# nrf7140_sysctrl register map
Vendor: Nordic Semiconductor; Series: nRF71; File version: 1
Registers are 32-bit, read-write, reset 0x0 unless marked. A register's access mark holds for its fields unless they carry their own. Offsets are from the block's base; [hi:lo] are bit positions; lines under a group give offsets from that group; {n}, {i} and the like mark numbered series; 'fields as' and 'values as' point back to an identical list.

## VREGMAIN — VREGMAIN peripheral
Base 0x5F961000
0x100 EVENTS_READY — Power up done
  [0] EVENTS_READY
    0=NotGenerated (Event not generated); 1=Generated (Event generated)
0x104 EVENTS_SETTLED — Settled flag for MODE handshake
  [0] EVENTS_SETTLED
    values as EVENTS_READY.EVENTS_READY
{0x104+4i} EVENTS_SETTLEDCH{i} (i=1..3) — Settled flag for CH{i} enable
  [0] EVENTS_SETTLEDCH{i}
    values as EVENTS_READY.EVENTS_READY
0x114 EVENTS_IOUTCMP — Analog current comparator
  [0] EVENTS_IOUTCMP
    values as EVENTS_READY.EVENTS_READY
0x118 EVENTS_LP2HP — Current consumption above threshold
  [0] EVENTS_LP2HP
    values as EVENTS_READY.EVENTS_READY
0x11C EVENTS_HP2LP — Current consumption below threshold
  [0] EVENTS_HP2LP
    values as EVENTS_READY.EVENTS_READY
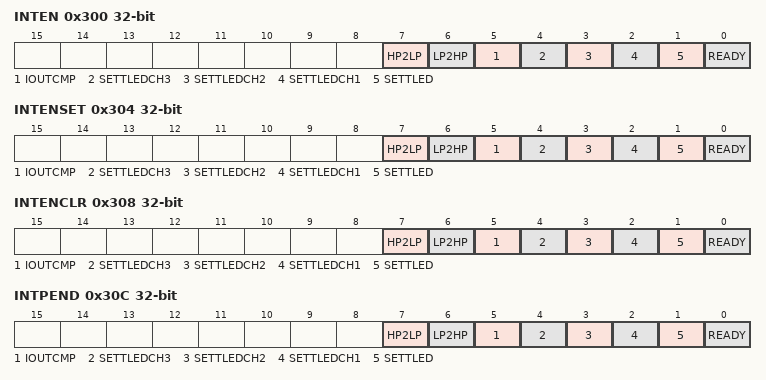
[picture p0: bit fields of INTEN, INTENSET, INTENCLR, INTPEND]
0x300 INTEN — Enable or disable interrupt
  [all] fields
    0=Disabled; 1=Enabled
  [7] HP2LP — Enable or disable interrupt for event HP2LP
  [6] LP2HP — Enable or disable interrupt for event LP2HP
  [5] IOUTCMP — Enable or disable interrupt for event IOUTCMP
  [4] SETTLEDCH3 — Enable or disable interrupt for event SETTLEDCH3
  [3] SETTLEDCH2 — Enable or disable interrupt for event SETTLEDCH2
  [2] SETTLEDCH1 — Enable or disable interrupt for event SETTLEDCH1
  [1] SETTLED — Enable or disable interrupt for event SETTLED
  [0] READY — Enable or disable interrupt for event READY
0x304 INTENSET — Enable interrupt
  [all] fields
    on read: 0=Disabled (Read: Disabled); 1=Enabled (Read: Enabled) | on write: 1=Set (Enable)
  [7] HP2LP — Write '1' to enable interrupt for event HP2LP
  [6] LP2HP — Write '1' to enable interrupt for event LP2HP
  [5] IOUTCMP — Write '1' to enable interrupt for event IOUTCMP
  [4] SETTLEDCH3 — Write '1' to enable interrupt for event SETTLEDCH3
  [3] SETTLEDCH2 — Write '1' to enable interrupt for event SETTLEDCH2
  [2] SETTLEDCH1 — Write '1' to enable interrupt for event SETTLEDCH1
  [1] SETTLED — Write '1' to enable interrupt for event SETTLED
  [0] READY — Write '1' to enable interrupt for event READY
0x308 INTENCLR — Disable interrupt
  [all] fields
    on read: 0=Disabled (Read: Disabled); 1=Enabled (Read: Enabled) | on write: 1=Clear (Disable)
  [7] HP2LP — Write '1' to disable interrupt for event HP2LP
  [6] LP2HP — Write '1' to disable interrupt for event LP2HP
  [5] IOUTCMP — Write '1' to disable interrupt for event IOUTCMP
  [4] SETTLEDCH3 — Write '1' to disable interrupt for event SETTLEDCH3
  [3] SETTLEDCH2 — Write '1' to disable interrupt for event SETTLEDCH2
  [2] SETTLEDCH1 — Write '1' to disable interrupt for event SETTLEDCH1
  [1] SETTLED — Write '1' to disable interrupt for event SETTLED
  [0] READY — Write '1' to disable interrupt for event READY
0x30C INTPEND ro — Pending interrupts
  [all] fields
    on read: 0=NotPending (Read: Not pending); 1=Pending (Read: Pending)
  [7] HP2LP — Read pending status of interrupt for event HP2LP
  [6] LP2HP — Read pending status of interrupt for event LP2HP
  [5] IOUTCMP — Read pending status of interrupt for event IOUTCMP
  [4] SETTLEDCH3 — Read pending status of interrupt for event SETTLEDCH3
  [3] SETTLEDCH2 — Read pending status of interrupt for event SETTLEDCH2
  [2] SETTLEDCH1 — Read pending status of interrupt for event SETTLEDCH1
  [1] SETTLED — Read pending status of interrupt for event SETTLED
  [0] READY — Read pending status of interrupt for event READY
0x400 STATUS — Current voltage regulator mode
  [1:0] MODE
    0=HP (High power hysteretic mode); 1=LP (Autonomous hysteretic low power mode); 2=ULP (Refresh based ultra-Low power mode); 3=PWM (PWM mode is fixed frequency DCDC operation mode)
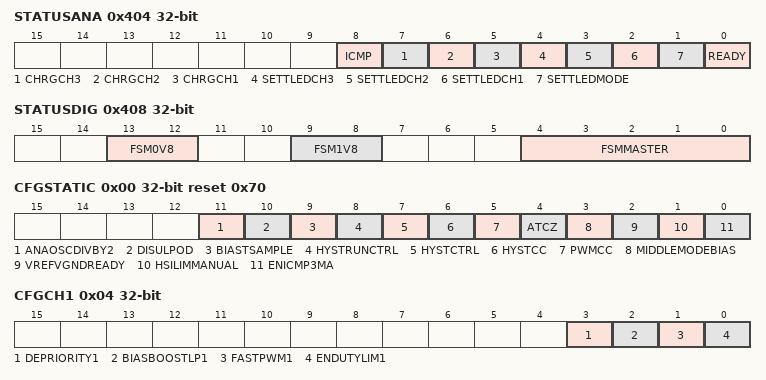
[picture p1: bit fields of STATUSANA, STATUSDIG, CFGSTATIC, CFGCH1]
0x404 STATUSANA ro — Status of analog module output signals
  [8] ICMP — Current value of the ICMP signal from the analog module
  [7] CHRGCH3 — Current value of the CH3 CHRG signal from the analog module
  [6] CHRGCH2 — Current value of the CH2 CHRG signal from the analog module
  [5] CHRGCH1 — Current value of the CH1 CHRG signal from the analog module
  [4] SETTLEDCH3 — Current value of the CH3 SETTLED signal from the analog module
  [3] SETTLEDCH2 — Current value of the CH2 SETTLED signal from the analog module
  [2] SETTLEDCH1 — Current value of the CH1 SETTLED signal from the analog module
  [1] SETTLEDMODE — Current value of the SETTLED_MODE signal from the analog module
  [0] READY — Current value of the READY signal from the analog module
0x408 STATUSDIG ro — Status of digital controllers
  [13:12] FSM0V8 — State of MMI 0V8 FSM
  [9:8] FSM1V8 — State of MMI 1V8 FSM
  [4:0] FSMMASTER — State of MMI master FSM
0x410 CONFIG group — Unspecified
  0x00 CFGSTATIC reset 0x70 — VREGMAIN static CFGC configuration
    [11] ANAOSCDIVBY2 — Divides OSC_ANA_RFR clock by 2
      0=Disabled (Configuration disabled); 1=Enabled (Configuration enabled)
    [10] DISULPOD — Keep nominal hysteresis in ULP mode. Will scale up with this configuration Disabled
      values as ANAOSCDIVBY2
    [9] BIASTSAMPLE — Elongates sample time for VREFs
      values as ANAOSCDIVBY2
    [8] HYSTRUNCTRL — Hysteresis feedback control
      0=HystVoutCmp (Hysteresis feedback from VOUTCMP); 1=HystMbiasCore (Hysteresis feedback on MBIAS_CORE pwrup)
    [7] HYSTCTRL — Controls amount of hysteresis
      0=Hyst4mV (4mV Hysteresis); 1=Hyst8mV (8mV hysteresis)
    [6] HYSTCC — Enables clamp function in HYST mode
      values as ANAOSCDIVBY2
    [5] PWMCC — Enables clamp function in PWM mode
      values as ANAOSCDIVBY2
    [4] ATCZ — Enbles auto-zero function for P_DCCHV zero cross comparator
      values as ANAOSCDIVBY2
    [3] MIDDLEMODEBIAS — Additional bias for enhanced response and ripple in LP hysteretic mode
      values as ANAOSCDIVBY2
    [2] VREFVGNDREADY — Vref gnd ready, alternative configuration
      values as ANAOSCDIVBY2
    [1] HSILIMMANUAL — Overrides coil current limit to prog value
      values as ANAOSCDIVBY2
    [0] ENICMP3MA — Enables DCDC current comparator
      values as ANAOSCDIVBY2
  0x04 CFGCH1 — VREGMAIN CH1 configuration
    [all] fields
      values as CONFIG.CFGSTATIC.ANAOSCDIVBY2
    [3] DEPRIORITY1 — Deprioritize CH1 for maxium current on CH2 and CH3
    [2] BIASBOOSTLP1 — Doubles bias current for VOUTCMP
    [1] FASTPWM1 — Faster loop for PWM modulator
    [0] ENDUTYLIM1 — Maximum duty cycle limitation
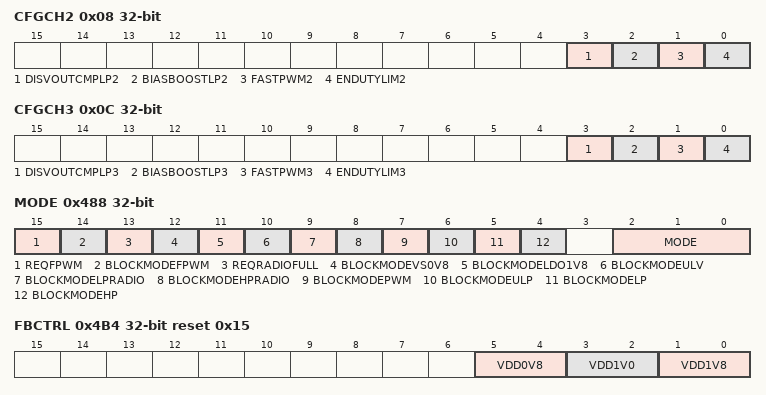
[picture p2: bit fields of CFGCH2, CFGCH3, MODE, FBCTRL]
  0x08 CFGCH2 — VREGMAIN CH2 configuration
    [all] fields
      values as CONFIG.CFGSTATIC.ANAOSCDIVBY2
    [3] DISVOUTCMPLP2 — Disables VOUT comparator in LP mode
    [2] BIASBOOSTLP2 — Doubles bias current for VOUTCMP
    [1] FASTPWM2 — Faster loop for PWM modulator
    [0] ENDUTYLIM2 — Maximum duty cycle limitation
  0x0C CFGCH3 — VREGMAIN CH3 configuration
    [all] fields
      values as CONFIG.CFGSTATIC.ANAOSCDIVBY2
    [3] DISVOUTCMPLP3 — Disables VOUT comparator in LP mode
    [2] BIASBOOSTLP3 — Doubles bias current for VOUTCMP
    [1] FASTPWM3 — Faster loop for PWM modulator
    [0] ENDUTYLIM3 — Maximum duty cycle limitation
0x440 TRIM group — Unspecified
  0x00 BIASIBPP — IBPP current trimming
    [2:0] VAL — Bias trim value
      0=Normal trim value; 1=The trim value is 23 percent; 2=The trim value is 54 percent; 3=The trim value is 98 percent; 4=ValNeg51 (The trim value is -51 percent); 5=ValNeg42 (The trim value is -42 percent); 6=ValNeg31 (The trim value is -31 percent); 7=ValNeg18 (The trim value is -18 percent)
  0x04 BIASIBPSR — IBPSR current and VREF voltage trimming
    [4:0] VAL — Bias trim value
  0x08 VDDAO1V8HYSTOUTPUT — VDD_AO_1V8 hysteretic (HYST) output voltage trimming
    [3:0] VAL — Trim value
  0x0C VDDAO1V8PWMOUTPUT — VDD_AO_1V8 PWM output voltage trimming
    [3:0] VAL — Trim value
  0x10 VDD1V0HYSTOUTPUT — VDD_1V0 hysteretic (HYST) output voltage trimming
    [3:0] VAL — Trim value
  0x14 VDDVS0V8HYSTOUTPUT — VDD_VS_0V8 hysteretic (HYST) output voltage trimming
    [3:0] VAL — Trim value
  0x18 VDDVS0V8PWMOUTPUT — VDD_VS_0V8 PWM output voltage trimming
    [3:0] VAL — Trim value
  0x1C VDD1V0PWMOUTPUT — VDD_1V0 PWM output voltage trimming
    [3:0] VAL — Voltage value
  0x20 ZCROSS — Zero cross detector trimming
    [3:0] VAL — Trim value
  0x24 HSILIM — HS current limiter trimming
    [2:0] VAL — Trim value
  0x28 ICMP — DCDC output current comparator trimming
    [1:0] VAL — Trim value
      0=DCDC output current comparator trim 0 percent; 1=DCDC output current comparator trim 25 percent; 2=ValNeg50 (DCDC output current comparator trim -50 percent); 3=ValNeg25 (DCDC output current comparator trim -25 percent)
  0x2C VGND — VGND trim
    [1:0] VAL — Trim value
0x480 MIRROR reset 0x1 — Enable LOCK for mirrored registers
  [0] LOCK — Lock for mirrored registers
    0=Disabled (Lock disabled); 1=Enabled (Lock enabled)
0x484 PWRUPCTRL — Power up control
  [1:0] CTRL
    0=Automatically handled by the peripheral; 1=PowerUp; 2=PowerDown
0x488 MODE — Voltage regulator mode
  [15] REQFPWM — Request FPWM mode. Upscale to WiFi power (1.1v)
    0=Disabled (Req disabled); 1=Enabled (Req enabled)
  [14] BLOCKMODEFPWM — Block FPWM mode while in MODE = Auto
    0=NotBlocked (Mode not blocked); 1=Blocked (Mode blocked)
  [13] REQRADIOFULL
    0=Disabled (Req disabled); 1=Enabled (Req enabled)
  [12] BLOCKMODEVS0V8 — Block VREGVS0V8 full mode request in MODE = Auto
    0=NotBlocked (Mode not blocked); 1=Blocked (Mode blocked)
  [11] BLOCKMODELDO1V8 — Block VREGAO1V8 full mode request in MODE = Auto
    0=NotBlocked (Mode not blocked); 1=Blocked (Mode blocked)
  [10] BLOCKMODEULV — Block ULV mode while in MODE = Auto
    0=NotBlocked (Mode not blocked); 1=Blocked (Mode blocked)
  [9] BLOCKMODELPRADIO — Block LP RADIO mode while in MODE = Auto
    0=NotBlocked (Mode not blocked); 1=Blocked (Mode blocked)
  [8] BLOCKMODEHPRADIO — Block HP RADIO mode while in MODE = Auto
    0=NotBlocked (Mode not blocked); 1=Blocked (Mode blocked)
  [7] BLOCKMODEPWM — Block PWM mode while in MODE = Auto
    0=NotBlocked (Mode not blocked); 1=Blocked (Mode blocked)
  [6] BLOCKMODEULP — Block ULP mode while in MODE = Auto
    0=NotBlocked (Mode not blocked); 1=Blocked (Mode blocked)
  [5] BLOCKMODELP — Block LP mode while in MODE = Auto
    0=NotBlocked (Mode not blocked); 1=Blocked (Mode blocked)
  [4] BLOCKMODEHP — Block HP mode while in MODE = Auto
    0=NotBlocked (Mode not blocked); 1=Blocked (Mode blocked)
  [2:0] MODE
    0=Automatically handled by the peripheral; 1=HP (High power hysteretic mode); 2=LP (Autonomous hysteretic low power mode); 3=ULP (Refresh based ultra-Low power mode); 4=PWM (PWM mode is fixed frequency DCDC operation mode); 5=FPWM (FPWM mode)
0x48C VDDAO1V8OUTPUT reset 0x4 — VDD_AO_1V8 output voltage
  [2:0] VAL — Voltage value
0x490 VDDAO1V8LPOUTPUT reset 0x4 — VDD_AO_1V8 Low Power output voltage
  [2:0] VAL — Voltage value
0x494 VDD1V0OUTPUT reset 0x1C — VDD_1V0 output voltage
  [5:0] VAL — Voltage value
0x498 VDD1V0OUTPUTRADIO reset 0x2B — VDD_1V0 output voltage, radio upscaling
  [5:0] VAL — Voltage value
0x49C VDD1V0LPOUTPUT reset 0x18 — VDD_1V0 LP output voltage
  [5:0] VAL — Voltage value
0x4A0 VDD1V0LPOUTPUTRADIO reset 0x2B — VDD_1V0 LP output voltage, radio upscaling
  [5:0] VAL — Voltage value
0x4A4 VDD1V0ULPOUTPUT reset 0x8 — VDD_1V0 ULP output voltage
  [5:0] VAL — Voltage value
0x4A8 VDDVS0V8OUTPUT reset 0x30 — VDD_VS_0V8 output voltage
  [5:0] VAL — Voltage value
0x4AC HSILIMPROG — HS current limiter program
  [1:0] VAL — HS current limiter value
    0=Val150mA (Current limit to 150mA); 1=Val250mA (Current limit to 250mA); 2=Val350mA (Current limit to 350mA); 3=Val450mA (Current limit to 450mA (PWM mode only))
0x4B0 PWMPROG — PWM program
  [1:0] VAL — PWM program value
    0=PWMVal0 (VDD_AO_1V8 = 1/3, VDD_1V0 = 1/3, VDD_VS_0V8 = 1/3); 1=PWMVal1 (VDD_AO_1V8 = 2/4, VDD_1V0 = 1/4, VDD_VS_0V8 = 1/4); 2=PWMVal2 (VDD_AO_1V8 = 1/4, VDD_1V0 = 2/4, VDD_VS_0V8 = 1/4); 3=PWMVal3 (VDD_AO_1V8 = 1/4, VDD_1V0 = 1/4, VDD_VS_0V8 = 2/4)
0x4B4 FBCTRL reset 0x15 — Regulator feedback point control
  [5:4] VDD0V8 — VDD_0V8 feedback configuration
    0=VDDVS0V8FB (VDD_VS_0V8 feedback); 1=SEC0V8FB (SEC_0V8 feedback); 3=VDDVS0V8SEC0V8FB (VDD_VS_0V8 and SEC_0V8 feedback)
  [3:2] VDD1V0 — VDD_1V0 feedback configuration
    0=VDD1V0FB (VDD_1V0 feedback); 1=SEC1V0FB (SEC_1V0 feedback); 2=VDDSEC1V0FB (VDD_1V0 and SEC_1V0 feedback); 3=VDDAOSEC1V0FB (VDD_AO_0V8 and SEC_1V0 feedback)
  [1:0] VDD1V8 — VDD_1V8 feedback configuration
    0=VDD1V8FB (VDD_1V8 feedback); 1=SEC1V8FB (SEC_1V8 feedback); 3=VDDSEC1V8FB (VDD_1V8 and SEC_1V8 feedback)
0x4B8 ITHRESHOLD reset 0xA — Current threshold for HP/LP mode transistion
  [3:0] VAL — Current consumption
0x4BC ITHRESHOLDPWM — Current threshold for half clock speed in PWM mode
  [3:0] VAL — Current consumption
0x4C0 ITHRESHOLD0V8LOW reset 0x2 — Current threshold LDO toggle at low 0V8 current consumption
  [3:0] VAL — Current consumption
0x500 OVERRIDE group — Unspecified
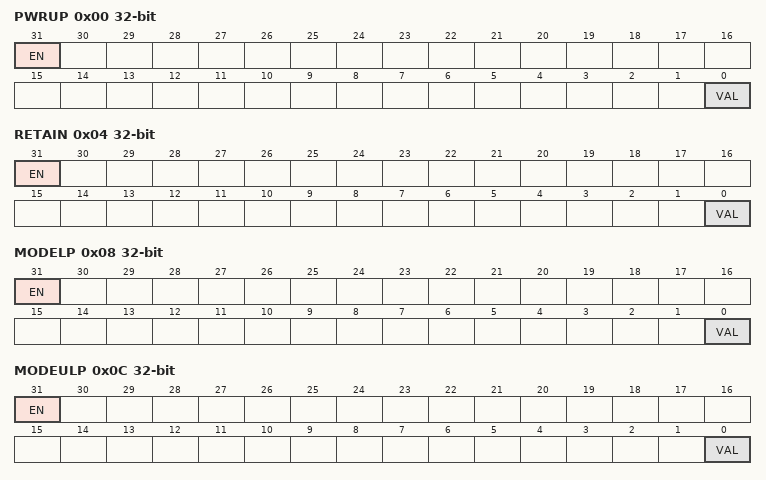
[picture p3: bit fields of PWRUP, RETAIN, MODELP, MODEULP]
  0x00 PWRUP — Override the PWRUP signal to the analog module
    [31] EN — Enable the override
      0=Disabled (Override is disabled); 1=Enabled (Override is enabled)
    [0] VAL — Override value for the signal
  0x04 RETAIN — Override the RETAIN signal to the analog module
    fields as OVERRIDE.PWRUP
  0x08 MODELP — Override the MODE_LP signal to the analog module
    fields as OVERRIDE.PWRUP
  0x0C MODEULP — Override the MODE_ULP signal to the analog module
    fields as OVERRIDE.PWRUP
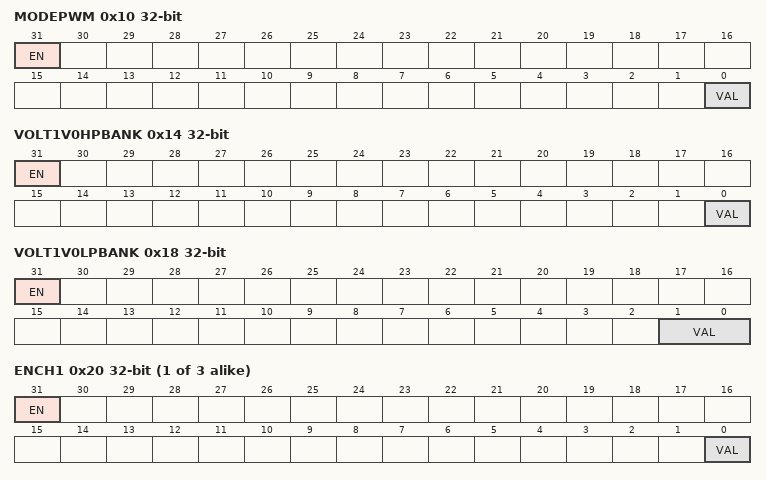
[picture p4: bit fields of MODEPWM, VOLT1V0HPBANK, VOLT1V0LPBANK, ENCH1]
  0x10 MODEPWM — Override the MODE_PWM signal to the analog module
    fields as OVERRIDE.PWRUP
  0x14 VOLT1V0HPBANK — Override the VOLT_HP_VDD1V0 bank select multiplexer
    fields as OVERRIDE.PWRUP
  0x18 VOLT1V0LPBANK — Override the VOLT_LP_VDD1V0 bank select multiplexer
    [31] EN — Enable the override
      values as OVERRIDE.PWRUP.EN
    [1:0] VAL — Override value for the signal
  0x1C CFGALLSTATIC — Route all CFG bits as static CFGs
    [31] EN — Enable the override
      values as OVERRIDE.PWRUP.EN
  {0x1C+4j} ENCH{j} (j=1..3) — Override the EN_CH{j} signal to the analog module
    fields as OVERRIDE.PWRUP
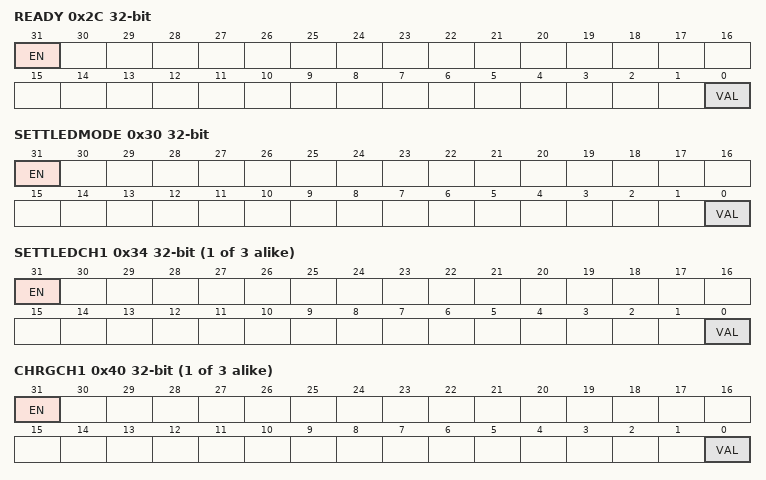
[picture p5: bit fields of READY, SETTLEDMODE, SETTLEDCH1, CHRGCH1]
  0x2C READY — Override the READY signal from the analog module
    [31] EN — Enable the override
      values as OVERRIDE.PWRUP.EN
    [0] VAL — Current value of the signal
  0x30 SETTLEDMODE — Override the SETTLED_MODE signal from the analog module
    fields as OVERRIDE.READY
  {0x30+4j} SETTLEDCH{j} (j=1..3) — Override the CH{j} SETTLED signal from the analog module
    fields as OVERRIDE.READY
  {0x3C+4j} CHRGCH{j} (j=1..3) — Override the CH{j} CHRG signal from the analog module
    fields as OVERRIDE.READY
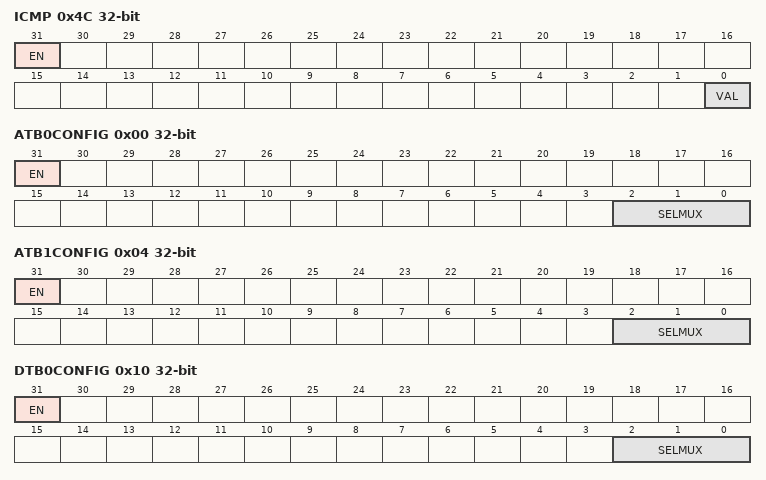
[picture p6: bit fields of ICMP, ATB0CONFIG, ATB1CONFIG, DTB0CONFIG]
  0x4C ICMP — Override the ICMP signal from the analog module
    fields as OVERRIDE.READY
0x600 DFT group — Unspecified
  0x00 ATB0CONFIG — Analog Test Bus 0 (ATB0) configuration
    [31] EN — Enable the analog test bus
      0=Disabled (Analog test bus is disabled); 1=Enabled (Analog test bus is enabled)
    [2:0] SELMUX — Select multiplexer for ATB0
      0=ATB0EXT (ATB0_EXT selected); 1=VFB0V9 (VFB_0V9 selected); 2=VFB1V0 (VFB_1V0 selected); 3=VFB0V8 (VFB_0V8 selected); 4=AVSSVGND (AVSS_VGND selected); 5=MBIASIBPP50N (MBIAS_IBPP_50N selected); 6=MBIASIBPSR8U (MBIAS_IBPSR_8U selected)
  0x04 ATB1CONFIG — Analog Test Bus 1 (ATB1) configuration
    [31] EN — Enable the analog test bus
      values as DFT.ATB0CONFIG.EN
    [2:0] SELMUX — Select multiplexer for ATB1
      1=VREF0V9 (VREF_0V9 selected); 2=VREF1V0 (VREF_1V0 selected); 3=VREF0V8 (VREF_0V8 selected); 4=VGNDREF5V (VGNDREF_5V selected); 5=MBIASVREF (MBIAS_VREF selected); 6=AVSSSIMO (AVSS_SIMO selected)
  0x10 DTB0CONFIG — Digital Test Bus 0 (DTB0) configuration
    [31] EN — Enable the digital test bus
      0=Disabled (Digital test bus is disabled); 1=Enabled (Digital test bus is enabled)
    [2:0] SELMUX — Select multiplexer for DTB0
      0=CLK (CLK selected); 1=IBPPREADY (IBPP_READY selected); 2=REQUESTMBIAS (REQUEST_MBIAS selected); 3=MBIASREADY (MBIAS_READY selected); 4=SELVOLTLP (SEL_VOLT_LP selected); 6=DRVHS (DRVHS selected); 7=MBIASSETTLED (MBIAS_SETTLED selected)
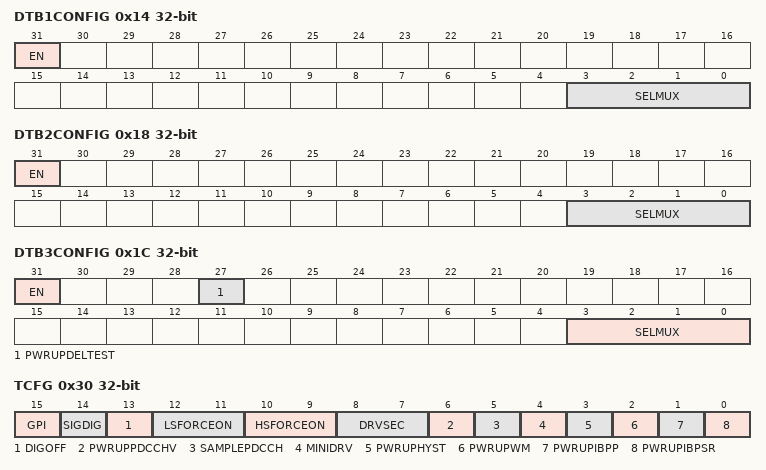
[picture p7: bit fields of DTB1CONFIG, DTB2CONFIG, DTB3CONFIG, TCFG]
  0x14 DTB1CONFIG — Digital Test Bus 1 (DTB1) configuration
    [31] EN — Enable the digital test bus
      values as DFT.DTB0CONFIG.EN
    [3:0] SELMUX — Select multiplexer for DTB1
      1=PWRUPCH1 (PWRUPCH1 selected); 2=VOUTCMP1 (VOUTCMP1 selected); 3=PWMCMP1 (PWMCMP1 selected); 4=DRVSEC1 (DRVSEC1 selected); 5=ZCROSS (ZCROSS selected); 6=PDCCHREADY (P_DCCH_READY selected); 8=MODELP (MODE_LP selected); 9=HVBUCKREADY (HVBUCK_READY selected); 10=SETTLEDCH3 (SETTLED_CH3 selected); 11=PWMILIM2 (PWM_ILIM2 selected); 12=PWMOC1 (PWM_OC1 selected); 13=PWMSKIP1 (PWM_SKIP1 selected); 14=PWMFAULT1 (PWM_FAULT1 selected); 15=CHRG1 (CHRG1 selected)
  0x18 DTB2CONFIG — Digital Test Bus 2 (DTB2) configuration
    [31] EN — Enable the digital test bus
      values as DFT.DTB0CONFIG.EN
    [3:0] SELMUX — Select multiplexer for DTB2
      0=PWRUPPWM (PWRUP_PWM selected); 1=PWRUPCH2 (PWRUPCH2 selected); 2=VOUTCMP3 (VOUTCMP3 selected); 3=PWMCMP2 (PWMCMP2 selected); 4=DRVSEC2 (DRVSEC2 selected); 5=HSLIM (HSLIM selected); 6=DRVLS (DRVLS selected); 8=MODEHP (MODE_HP selected); 9=HVBUCKSETTLED (HVBUCK_SETTLED selected); 10=SETTLEDCH1 (SETTLED_CH1 selected); 11=PWMLIM11V8 (PWM_LIM1_1V8 selected); 12=PWMOC2 (PWM_OC2 selected); 13=PWMSKIP2 (PWM_SKIP2 selected); 14=PWMFAULT2 (PWM_FAULT2 selected); 15=CHRG2 (CHRG2 selected)
  0x1C DTB3CONFIG — Digital Test Bus 3 (DTB3) configuration
    [31] EN — Enable the digital test bus
      values as DFT.DTB0CONFIG.EN
    [27] PWRUPDELTEST — Enable the PWRUP delay test circuit
      0=Disabled (PWRUP delay test circuit is disabled); 1=Enabled (PWRUP delay test circuit is enabled)
    [3:0] SELMUX — Select multiplexer for DTB3
      0=PWRUPHYST (PWRUP_HYST selected); 1=PWRUPCH3 (PWRUPCH3 selected); 2=VOUTCMP2 (VOUTCMP2 selected); 3=PWMCMP3 (PWMCMP3 selected); 4=DRVSEC3 (DRVSEC3 selected); 5=SECREADY (SECREADY selected); 8=MODEPWM (MODE_PWM selected); 10=SETTLEDCH2 (SETTLED_CH2 selected); 11=PWMILIM31V8 (PWM_ILIM3_1V8 selected); 12=PWMOC3 (PWM_OC3 selected); 13=PWMSKIP3 (PWM_SKIP3 selected); 14=PWMFAULT2 (PWM_FAULT2 selected); 15=CHRG3 (CHRG3 selected)
  0x30 TCFG — Test mode configuration
    [15] GPI — Enable GPI (PSEUDO PWM)
      0=Disabled (GPI disabled); 1=Enabled (GPI enabled)
    [14] SIGDIG — Enable SIGDIG
      0=Disabled (SIGDIG disabled); 1=Enabled (SIGDIG enabled)
    [13] DIGOFF — Enable DIGOFF
      0=Disabled (DIGOFF disabled); 1=Enabled (DIGOFF enabled)
    [12:11] LSFORCEON — Enable LS force on
      0=Normal mode; 1=LS force off-zx gating; 2=GPI; 3=LSforceon
    [10:9] HSFORCEON — Enable HS force on
      0=Normal mode; 1=HSILIM (HS force on HSILIM gating); 2=GPI; 3=HSforceon
    [8:7] DRVSEC — Select DRVSEC
      0=Normal mode, DRVSEC2 in reset; 1=DRVSEC1 selected; 2=DRVSEC2 selected; 3=OFF
    [6] PWRUPPDCCHV — Enable mux PWRUP_P_DCCHV
      0=Disabled (PWRUPPDCCHV disabled); 1=Enabled (PWRUPPDCCHV enabled)
    [5] SAMPLEPDCCH — Sample P_DCCH by ready
      0=Disabled (Sample P_DCCH disabled); 1=Enabled (Sample P_DCCH enabled)
    [4] MINIDRV — Enable MINIDRV
      0=Disabled (MINIDRV disabled); 1=Enabled (MINIDRV enabled)
    [3] PWRUPHYST — Enable PWRUP_HYST
      0=Disabled (PWRUP_HYST disabled); 1=Enabled (PWRUP_HYST enabled)
    [2] PWRUPWM — Enable PWRUP_PWM
      0=Disabled (PWRUP_PWM disabled); 1=Enabled (PWRUP_PWM enabled)
    [1] PWRUPIBPP — Enable PWRUP_IBPP
      0=Disabled (PWRUP_IBPP disabled); 1=Enabled (PWRUP_IBPP enabled)
    [0] PWRUPIBPSR — Enable PWRUP_IBPSR
      0=Disabled (PWRUP_IBPSR disabled); 1=Enabled (PWRUP_IBPSR enabled)
  0x34 CALEN — Calibration enable
    [0] CALEN
      0=ATCMPOff; 1=ATCMPOn
  0x38 CALCMP ro — Calibration compare
    [0] CALCMP
